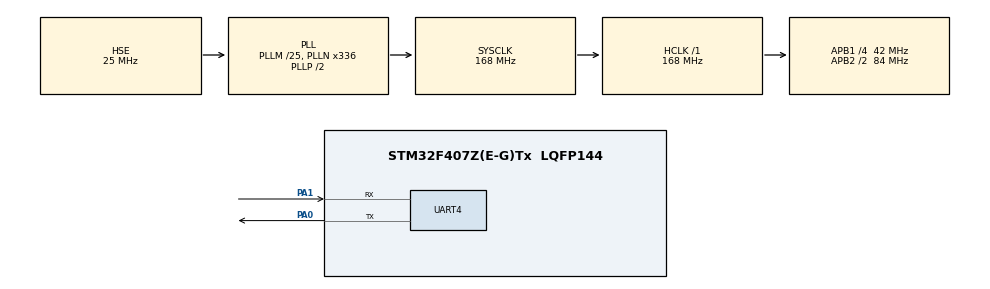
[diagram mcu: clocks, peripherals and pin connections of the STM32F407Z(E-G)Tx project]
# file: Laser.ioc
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Dma.Request0=UART4_RX
Dma.Request1=UART4_TX
Dma.UART4_RX.0.Direction=DMA_PERIPH_TO_MEMORY
Dma.UART4_RX.0.FIFOMode=DMA_FIFOMODE_DISABLE
Dma.UART4_RX.0.Instance=DMA1_Stream2
Dma.UART4_RX.0.MemDataAlignment=DMA_MDATAALIGN_BYTE
Dma.UART4_RX.0.MemInc=DMA_MINC_ENABLE
Dma.UART4_RX.0.Mode=DMA_CIRCULAR
Dma.UART4_RX.0.PeriphDataAlignment=DMA_PDATAALIGN_BYTE
Dma.UART4_RX.0.PeriphInc=DMA_PINC_DISABLE
Dma.UART4_RX.0.Priority=DMA_PRIORITY_LOW
Dma.UART4_TX.1.Direction=DMA_MEMORY_TO_PERIPH
Dma.UART4_TX.1.FIFOMode=DMA_FIFOMODE_DISABLE
Dma.UART4_TX.1.Instance=DMA1_Stream4
Dma.UART4_TX.1.MemDataAlignment=DMA_MDATAALIGN_BYTE
Dma.UART4_TX.1.MemInc=DMA_MINC_ENABLE
Dma.UART4_TX.1.Mode=DMA_NORMAL
Dma.UART4_TX.1.PeriphDataAlignment=DMA_PDATAALIGN_BYTE
Dma.UART4_TX.1.PeriphInc=DMA_PINC_DISABLE
Dma.UART4_TX.1.Priority=DMA_PRIORITY_LOW
FREERTOS.Tasks01=defaultTask,0,128,StartDefaultTask,Default,NULL,Dynamic,NULL,NULL;ControlTask,0,1024,Control_Task,As weak,NULL,Dynamic,NULL,NULL
Mcu.Family=STM32F4
Mcu.Name=STM32F407Z(E-G)Tx
Mcu.Package=LQFP144
NVIC.DMA1_Stream2_IRQn=true\:5\:0\:false\:false\:true\:true\:false\:true
NVIC.DMA1_Stream4_IRQn=true\:5\:0\:false\:false\:true\:true\:false\:true
NVIC.PriorityGroup=NVIC_PRIORITYGROUP_4
NVIC.TIM2_IRQn=true\:15\:0\:false\:false\:true\:false\:false\:true
NVIC.TimeBase=TIM2_IRQn
NVIC.TimeBaseIP=TIM2
NVIC.UART4_IRQn=true\:5\:0\:false\:false\:true\:true\:true\:true
PA0-WKUP.Mode=Asynchronous
PA0-WKUP.Signal=UART4_TX
PA1.Mode=Asynchronous
PA1.Signal=UART4_RX
PA13.Mode=Serial_Wire
PA13.Signal=SYS_JTMS-SWDIO
PA14.Mode=Serial_Wire
PA14.Signal=SYS_JTCK-SWCLK
PH0-OSC_IN.Mode=HSE-External-Oscillator
PH0-OSC_IN.Signal=RCC_OSC_IN
PH1-OSC_OUT.Mode=HSE-External-Oscillator
PH1-OSC_OUT.Signal=RCC_OSC_OUT
ProjectManager.HeapSize=0x200
ProjectManager.StackSize=0x400
ProjectManager.TargetToolchain=MDK-ARM V5.32
RCC.48MHZClocksFreq_Value=84000000
RCC.AHBFreq_Value=168000000
RCC.APB1CLKDivider=RCC_HCLK_DIV4
RCC.APB1Freq_Value=42000000
RCC.APB1TimFreq_Value=84000000
RCC.APB2CLKDivider=RCC_HCLK_DIV2
RCC.APB2Freq_Value=84000000
RCC.APB2TimFreq_Value=168000000
RCC.CortexFreq_Value=168000000
RCC.HCLKFreq_Value=168000000
RCC.HSE_VALUE=25000000
RCC.HSI_VALUE=16000000
RCC.LSE_VALUE=32768
RCC.PLLM=25
RCC.PLLN=336
RCC.PLLSourceVirtual=RCC_PLLSOURCE_HSE
RCC.SYSCLKFreq_VALUE=168000000
RCC.SYSCLKSource=RCC_SYSCLKSOURCE_PLLCLK
RCC.VCOOutputFreq_Value=336000000
UART4.VirtualMode=Asynchronous
VP_FREERTOS_VS_CMSIS_V1.Mode=CMSIS_V1
VP_SYS_VS_tim2.Mode=TIM2
board=custom

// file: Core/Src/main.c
/* USER CODE BEGIN Header */
/**
  ******************************************************************************
  * @file           : main.c
  * @brief          : Main program body
  ******************************************************************************
  * @attention
  *
  * Copyright (c) 2023 STMicroelectronics.
  * All rights reserved.
  *
  * This software is licensed under terms that can be found in the LICENSE file
  * in the root directory of this software component.
  * If no LICENSE file comes with this software, it is provided AS-IS.
  *
  ******************************************************************************
  */
/* USER CODE END Header */
#include "main.h"
#include "cmsis_os.h"

/* USER CODE BEGIN Includes */
#include "drv_uart.h"
/* USER CODE END Includes */

UART_HandleTypeDef huart4;
DMA_HandleTypeDef hdma_uart4_rx;
DMA_HandleTypeDef hdma_uart4_tx;

osThreadId defaultTaskHandle;
osThreadId ControlTaskHandle;

void SystemClock_Config(void);
static void MX_GPIO_Init(void);
static void MX_DMA_Init(void);
static void MX_UART4_Init(void);
void StartDefaultTask(void const * argument);
void Control_Task(void const * argument);

int main(void)
{

  /* MCU Configuration--------------------------------------------------------*/

  /* Reset of all peripherals, Initializes the Flash interface and the Systick. */
  HAL_Init();

  /* Configure the system clock */
  SystemClock_Config();

  /* Initialize all configured peripherals */
  MX_GPIO_Init();
  MX_DMA_Init();
  MX_UART4_Init();
  /* USER CODE BEGIN 2 */
  USART4_Init();
  /* USER CODE END 2 */

  /* Create the thread(s) */
  /* definition and creation of defaultTask */
  osThreadDef(defaultTask, StartDefaultTask, osPriorityNormal, 0, 128);
  defaultTaskHandle = osThreadCreate(osThread(defaultTask), NULL);

  /* definition and creation of ControlTask */
  osThreadDef(ControlTask, Control_Task, osPriorityNormal, 0, 1024);
  ControlTaskHandle = osThreadCreate(osThread(ControlTask), NULL);

  /* Start scheduler */
  osKernelStart();

  /* We should never get here as control is now taken by the scheduler */
  /* Infinite loop */
  while (1)
  {

  }
}

void SystemClock_Config(void)
{
  RCC_OscInitTypeDef RCC_OscInitStruct = {0};
  RCC_ClkInitTypeDef RCC_ClkInitStruct = {0};

  /** Configure the main internal regulator output voltage
  */
  __HAL_RCC_PWR_CLK_ENABLE();
  __HAL_PWR_VOLTAGESCALING_CONFIG(PWR_REGULATOR_VOLTAGE_SCALE1);
  /** Initializes the RCC Oscillators according to the specified parameters
  * in the RCC_OscInitTypeDef structure.
  */
  RCC_OscInitStruct.OscillatorType = RCC_OSCILLATORTYPE_HSE;
  RCC_OscInitStruct.HSEState = RCC_HSE_ON;
  RCC_OscInitStruct.PLL.PLLState = RCC_PLL_ON;
  RCC_OscInitStruct.PLL.PLLSource = RCC_PLLSOURCE_HSE;
  RCC_OscInitStruct.PLL.PLLM = 25;
  RCC_OscInitStruct.PLL.PLLN = 336;
  RCC_OscInitStruct.PLL.PLLP = RCC_PLLP_DIV2;
  RCC_OscInitStruct.PLL.PLLQ = 4;
  if (HAL_RCC_OscConfig(&RCC_OscInitStruct) != HAL_OK)
  {
    Error_Handler();
  }
  /** Initializes the CPU, AHB and APB buses clocks
  */
  RCC_ClkInitStruct.ClockType = RCC_CLOCKTYPE_HCLK|RCC_CLOCKTYPE_SYSCLK
                              |RCC_CLOCKTYPE_PCLK1|RCC_CLOCKTYPE_PCLK2;
  RCC_ClkInitStruct.SYSCLKSource = RCC_SYSCLKSOURCE_PLLCLK;
  RCC_ClkInitStruct.AHBCLKDivider = RCC_SYSCLK_DIV1;
  RCC_ClkInitStruct.APB1CLKDivider = RCC_HCLK_DIV4;
  RCC_ClkInitStruct.APB2CLKDivider = RCC_HCLK_DIV2;

  if (HAL_RCC_ClockConfig(&RCC_ClkInitStruct, FLASH_LATENCY_5) != HAL_OK)
  {
    Error_Handler();
  }
}

static void MX_UART4_Init(void)
{

  huart4.Instance = UART4;
  huart4.Init.BaudRate = 115200;
  huart4.Init.WordLength = UART_WORDLENGTH_8B;
  huart4.Init.StopBits = UART_STOPBITS_1;
  huart4.Init.Parity = UART_PARITY_NONE;
  huart4.Init.Mode = UART_MODE_TX_RX;
  huart4.Init.HwFlowCtl = UART_HWCONTROL_NONE;
  huart4.Init.OverSampling = UART_OVERSAMPLING_16;
  if (HAL_UART_Init(&huart4) != HAL_OK)
  {
    Error_Handler();
  }

}

static void MX_DMA_Init(void)
{

  /* DMA controller clock enable */
  __HAL_RCC_DMA1_CLK_ENABLE();

  /* DMA interrupt init */
  /* DMA1_Stream2_IRQn interrupt configuration */
  HAL_NVIC_SetPriority(DMA1_Stream2_IRQn, 5, 0);
  HAL_NVIC_EnableIRQ(DMA1_Stream2_IRQn);
  /* DMA1_Stream4_IRQn interrupt configuration */
  HAL_NVIC_SetPriority(DMA1_Stream4_IRQn, 5, 0);
  HAL_NVIC_EnableIRQ(DMA1_Stream4_IRQn);

}

static void MX_GPIO_Init(void)
{

  /* GPIO Ports Clock Enable */
  __HAL_RCC_GPIOH_CLK_ENABLE();
  __HAL_RCC_GPIOA_CLK_ENABLE();

}

void StartDefaultTask(void const * argument)
{
  for(;;)
  {
    osDelay(1);
  }
}

__weak void Control_Task(void const * argument)
{
  for(;;)
  {
    osDelay(1);
  }
}

void HAL_TIM_PeriodElapsedCallback(TIM_HandleTypeDef *htim)
{
  if (htim->Instance == TIM2) {
    HAL_IncTick();
  }
}

void Error_Handler(void)
{
  __disable_irq();
  while (1)
  {
  }
}
